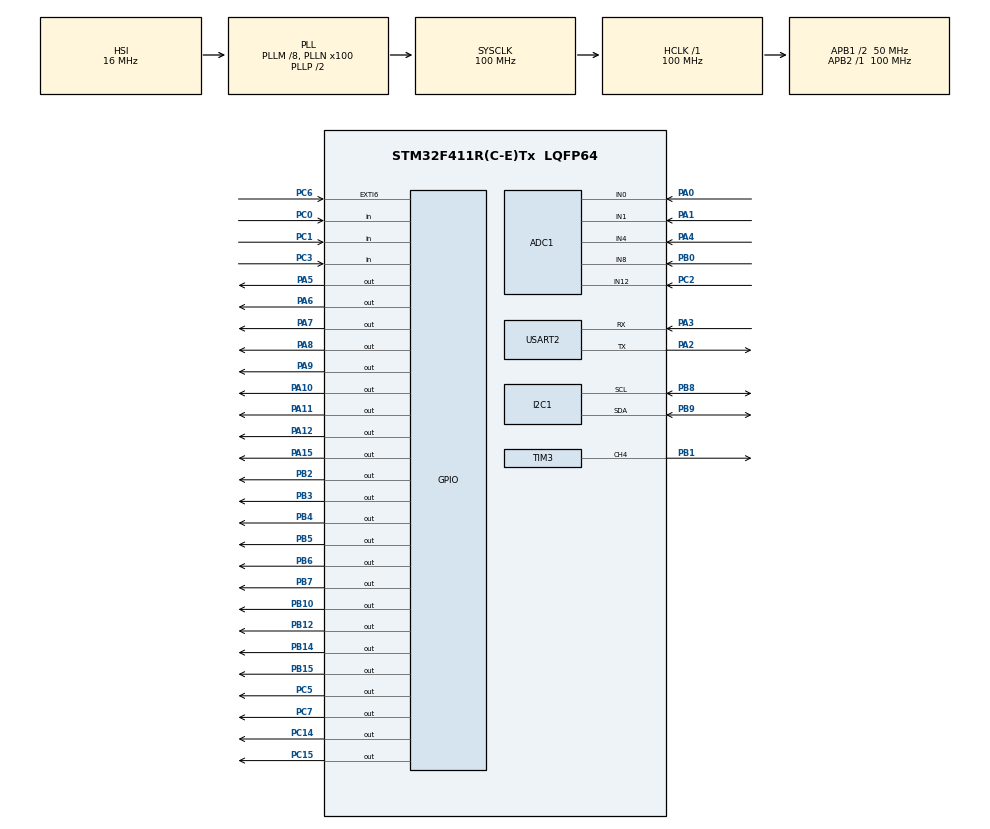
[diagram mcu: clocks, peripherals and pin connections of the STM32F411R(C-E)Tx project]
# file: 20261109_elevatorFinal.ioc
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ADC1.Channel-0\#ChannelRegularConversion=ADC_CHANNEL_1
ADC1.Channel-3\#ChannelRegularConversion=ADC_CHANNEL_4
ADC1.Channel-4\#ChannelRegularConversion=ADC_CHANNEL_8
ADC1.Channel-5\#ChannelRegularConversion=ADC_CHANNEL_12
ADC1.Channel-6\#ChannelRegularConversion=ADC_CHANNEL_0
ADC1.ContinuousConvMode=ENABLE
ADC1.DMAContinuousRequests=ENABLE
ADC1.NbrOfConversion=5
ADC1.NbrOfConversionFlag=1
ADC1.Rank-3\#ChannelRegularConversion=2
ADC1.Rank-4\#ChannelRegularConversion=3
ADC1.Rank-5\#ChannelRegularConversion=4
ADC1.Rank-6\#ChannelRegularConversion=5
ADC1.SamplingTime-0\#ChannelRegularConversion=ADC_SAMPLETIME_480CYCLES
ADC1.SamplingTime-3\#ChannelRegularConversion=ADC_SAMPLETIME_480CYCLES
ADC1.SamplingTime-4\#ChannelRegularConversion=ADC_SAMPLETIME_480CYCLES
ADC1.SamplingTime-5\#ChannelRegularConversion=ADC_SAMPLETIME_480CYCLES
ADC1.SamplingTime-6\#ChannelRegularConversion=ADC_SAMPLETIME_480CYCLES
ADC1.master=1
Dma.ADC1.0.Direction=DMA_PERIPH_TO_MEMORY
Dma.ADC1.0.FIFOMode=DMA_FIFOMODE_DISABLE
Dma.ADC1.0.Instance=DMA2_Stream0
Dma.ADC1.0.MemDataAlignment=DMA_MDATAALIGN_HALFWORD
Dma.ADC1.0.MemInc=DMA_MINC_ENABLE
Dma.ADC1.0.Mode=DMA_CIRCULAR
Dma.ADC1.0.PeriphDataAlignment=DMA_PDATAALIGN_HALFWORD
Dma.ADC1.0.PeriphInc=DMA_PINC_DISABLE
Dma.ADC1.0.Priority=DMA_PRIORITY_LOW
Dma.Request0=ADC1
Mcu.Family=STM32F4
Mcu.Name=STM32F411R(C-E)Tx
Mcu.Package=LQFP64
NVIC.DMA2_Stream0_IRQn=true\:0\:0\:false\:false\:true\:false\:true\:true
NVIC.EXTI9_5_IRQn=true\:0\:0\:false\:false\:true\:true\:true\:true
NVIC.PriorityGroup=NVIC_PRIORITYGROUP_4
NVIC.TIM2_IRQn=true\:0\:0\:false\:false\:true\:true\:true\:true
NVIC.TIM4_IRQn=true\:0\:0\:false\:false\:true\:true\:true\:true
NVIC.TIM5_IRQn=true\:0\:0\:false\:false\:true\:true\:true\:true
NVIC.USART2_IRQn=true\:0\:0\:false\:false\:true\:true\:true\:true
PA0-WKUP.Signal=ADCx_IN0
PA1.Signal=ADCx_IN1
PA10.Signal=GPIO_Output
PA11.Signal=GPIO_Output
PA12.Signal=GPIO_Output
PA15.Signal=GPIO_Output
PA2.Mode=Asynchronous
PA2.Signal=USART2_TX
PA3.Mode=Asynchronous
PA3.Signal=USART2_RX
PA4.Signal=ADCx_IN4
PA5.Signal=GPIO_Output
PA6.Signal=GPIO_Output
PA7.Signal=GPIO_Output
PA8.Signal=GPIO_Output
PA9.Signal=GPIO_Output
PB0.Signal=ADCx_IN8
PB1.Signal=S_TIM3_CH4
PB10.Signal=GPIO_Output
PB12.Signal=GPIO_Output
PB14.Signal=GPIO_Output
PB15.Signal=GPIO_Output
PB2.Signal=GPIO_Output
PB3.Signal=GPIO_Output
PB4.Signal=GPIO_Output
PB5.Signal=GPIO_Output
PB6.Signal=GPIO_Output
PB7.Signal=GPIO_Output
PB8.Mode=I2C
PB8.Signal=I2C1_SCL
PB9.Mode=I2C
PB9.Signal=I2C1_SDA
PC0.Signal=GPIO_Input
PC1.Signal=GPIO_Input
PC14-OSC32_IN.Signal=GPIO_Output
PC15-OSC32_OUT.Signal=GPIO_Output
PC2.Signal=ADCx_IN12
PC3.Signal=GPIO_Input
PC5.Signal=GPIO_Output
PC6.GPIO_ModeDefaultEXTI=GPIO_MODE_IT_RISING_FALLING
PC6.Signal=GPXTI6
PC7.Signal=GPIO_Output
PH0\ -\ OSC_IN.Mode=HSE-External-Oscillator
PH0\ -\ OSC_IN.Signal=RCC_OSC_IN
PH1\ -\ OSC_OUT.Mode=HSE-External-Oscillator
PH1\ -\ OSC_OUT.Signal=RCC_OSC_OUT
ProjectManager.HeapSize=0x200
ProjectManager.StackSize=0x400
ProjectManager.TargetToolchain=STM32CubeIDE
RCC.48MHZClocksFreq_Value=50000000
RCC.AHBFreq_Value=100000000
RCC.APB1CLKDivider=RCC_HCLK_DIV2
RCC.APB1Freq_Value=50000000
RCC.APB1TimFreq_Value=100000000
RCC.APB2Freq_Value=100000000
RCC.APB2TimFreq_Value=100000000
RCC.CortexFreq_Value=100000000
RCC.HCLKFreq_Value=100000000
RCC.HSE_VALUE=8000000
RCC.HSI_VALUE=16000000
RCC.LSE_VALUE=32768
RCC.PLLM=8
RCC.PLLN=100
RCC.SYSCLKFreq_VALUE=100000000
RCC.SYSCLKSource=RCC_SYSCLKSOURCE_PLLCLK
RCC.VCOOutputFreq_Value=200000000
SH.ADCx_IN0.0=ADC1_IN0,IN0
SH.ADCx_IN1.0=ADC1_IN1,IN1
SH.ADCx_IN12.0=ADC1_IN12,IN12
SH.ADCx_IN4.0=ADC1_IN4,IN4
SH.ADCx_IN8.0=ADC1_IN8,IN8
SH.S_TIM3_CH4.0=TIM3_CH4,PWM Generation4 CH4
TIM10.Prescaler=100-1
TIM2.Period=2000-1
TIM2.Prescaler=100-1
TIM3.Channel-PWM\ Generation4\ CH4=TIM_CHANNEL_4
TIM3.Period=65535
TIM3.Prescaler=100-1
TIM4.Period=1000-1
TIM4.Prescaler=100-1
TIM5.Period=1000-1
TIM5.Prescaler=100-1
USART2.VirtualMode=VM_ASYNC
VP_TIM10_VS_ClockSourceINT.Mode=Enable_Timer
VP_TIM2_VS_ClockSourceINT.Mode=Internal
VP_TIM3_VS_ClockSourceINT.Mode=Internal
VP_TIM4_VS_ClockSourceINT.Mode=Internal
VP_TIM5_VS_ClockSourceINT.Mode=Internal
board=custom

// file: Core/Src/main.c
/* USER CODE BEGIN Header */
/**
  ******************************************************************************
  * @file           : main.c
  * @brief          : Main program body
  ******************************************************************************
  * @attention
  *
  * Copyright (c) 2026 STMicroelectronics.
  * All rights reserved.
  *
  * This software is licensed under terms that can be found in the LICENSE file
  * in the root directory of this software component.
  * If no LICENSE file comes with this software, it is provided AS-IS.
  *
  ******************************************************************************
  */
/* USER CODE END Header */
#include "main.h"

/* USER CODE BEGIN Includes */
#include "ap/ap_main.h"
/* USER CODE END Includes */

ADC_HandleTypeDef hadc1;
DMA_HandleTypeDef hdma_adc1;

I2C_HandleTypeDef hi2c1;

TIM_HandleTypeDef htim2;
TIM_HandleTypeDef htim3;
TIM_HandleTypeDef htim4;
TIM_HandleTypeDef htim5;
TIM_HandleTypeDef htim10;

UART_HandleTypeDef huart2;

void SystemClock_Config(void);
static void MX_GPIO_Init(void);
static void MX_DMA_Init(void);
static void MX_ADC1_Init(void);
static void MX_TIM3_Init(void);
static void MX_I2C1_Init(void);
static void MX_TIM10_Init(void);
static void MX_TIM4_Init(void);
static void MX_USART2_UART_Init(void);
static void MX_TIM2_Init(void);
static void MX_TIM5_Init(void);

int main(void)
{

  /* MCU Configuration--------------------------------------------------------*/

  /* Reset of all peripherals, Initializes the Flash interface and the Systick. */
  HAL_Init();

  /* Configure the system clock */
  SystemClock_Config();

  /* Initialize all configured peripherals */
  MX_GPIO_Init();
  MX_DMA_Init();
  MX_ADC1_Init();
  MX_TIM3_Init();
  MX_I2C1_Init();
  MX_TIM10_Init();
  MX_TIM4_Init();
  MX_USART2_UART_Init();
  MX_TIM2_Init();
  MX_TIM5_Init();

  /* Infinite loop */
  /* USER CODE BEGIN WHILE */
//  ap_main();

  while (1)
  {

	  ap_main();

    /* USER CODE END WHILE */

  }
}

void SystemClock_Config(void)
{
  RCC_OscInitTypeDef RCC_OscInitStruct = {0};
  RCC_ClkInitTypeDef RCC_ClkInitStruct = {0};

  /** Configure the main internal regulator output voltage
  */
  __HAL_RCC_PWR_CLK_ENABLE();
  __HAL_PWR_VOLTAGESCALING_CONFIG(PWR_REGULATOR_VOLTAGE_SCALE1);

  /** Initializes the RCC Oscillators according to the specified parameters
  * in the RCC_OscInitTypeDef structure.
  */
  RCC_OscInitStruct.OscillatorType = RCC_OSCILLATORTYPE_HSI;
  RCC_OscInitStruct.HSIState = RCC_HSI_ON;
  RCC_OscInitStruct.HSICalibrationValue = RCC_HSICALIBRATION_DEFAULT;
  RCC_OscInitStruct.PLL.PLLState = RCC_PLL_ON;
  RCC_OscInitStruct.PLL.PLLSource = RCC_PLLSOURCE_HSI;
  RCC_OscInitStruct.PLL.PLLM = 8;
  RCC_OscInitStruct.PLL.PLLN = 100;
  RCC_OscInitStruct.PLL.PLLP = RCC_PLLP_DIV2;
  RCC_OscInitStruct.PLL.PLLQ = 4;
  if (HAL_RCC_OscConfig(&RCC_OscInitStruct) != HAL_OK)
  {
    Error_Handler();
  }

  /** Initializes the CPU, AHB and APB buses clocks
  */
  RCC_ClkInitStruct.ClockType = RCC_CLOCKTYPE_HCLK|RCC_CLOCKTYPE_SYSCLK
                              |RCC_CLOCKTYPE_PCLK1|RCC_CLOCKTYPE_PCLK2;
  RCC_ClkInitStruct.SYSCLKSource = RCC_SYSCLKSOURCE_PLLCLK;
  RCC_ClkInitStruct.AHBCLKDivider = RCC_SYSCLK_DIV1;
  RCC_ClkInitStruct.APB1CLKDivider = RCC_HCLK_DIV2;
  RCC_ClkInitStruct.APB2CLKDivider = RCC_HCLK_DIV1;

  if (HAL_RCC_ClockConfig(&RCC_ClkInitStruct, FLASH_LATENCY_3) != HAL_OK)
  {
    Error_Handler();
  }
}

static void MX_ADC1_Init(void)
{

  ADC_ChannelConfTypeDef sConfig = {0};

  /** Configure the global features of the ADC (Clock, Resolution, Data Alignment and number of conversion)
  */
  hadc1.Instance = ADC1;
  hadc1.Init.ClockPrescaler = ADC_CLOCK_SYNC_PCLK_DIV4;
  hadc1.Init.Resolution = ADC_RESOLUTION_12B;
  hadc1.Init.ScanConvMode = ENABLE;
  hadc1.Init.ContinuousConvMode = ENABLE;
  hadc1.Init.DiscontinuousConvMode = DISABLE;
  hadc1.Init.ExternalTrigConvEdge = ADC_EXTERNALTRIGCONVEDGE_NONE;
  hadc1.Init.ExternalTrigConv = ADC_SOFTWARE_START;
  hadc1.Init.DataAlign = ADC_DATAALIGN_RIGHT;
  hadc1.Init.NbrOfConversion = 5;
  hadc1.Init.DMAContinuousRequests = ENABLE;
  hadc1.Init.EOCSelection = ADC_EOC_SINGLE_CONV;
  if (HAL_ADC_Init(&hadc1) != HAL_OK)
  {
    Error_Handler();
  }

  /** Configure for the selected ADC regular channel its corresponding rank in the sequencer and its sample time.
  */
  sConfig.Channel = ADC_CHANNEL_1;
  sConfig.Rank = 1;
  sConfig.SamplingTime = ADC_SAMPLETIME_480CYCLES;
  if (HAL_ADC_ConfigChannel(&hadc1, &sConfig) != HAL_OK)
  {
    Error_Handler();
  }

  /** Configure for the selected ADC regular channel its corresponding rank in the sequencer and its sample time.
  */
  sConfig.Channel = ADC_CHANNEL_4;
  sConfig.Rank = 2;
  if (HAL_ADC_ConfigChannel(&hadc1, &sConfig) != HAL_OK)
  {
    Error_Handler();
  }

  /** Configure for the selected ADC regular channel its corresponding rank in the sequencer and its sample time.
  */
  sConfig.Channel = ADC_CHANNEL_8;
  sConfig.Rank = 3;
  if (HAL_ADC_ConfigChannel(&hadc1, &sConfig) != HAL_OK)
  {
    Error_Handler();
  }

  /** Configure for the selected ADC regular channel its corresponding rank in the sequencer and its sample time.
  */
  sConfig.Channel = ADC_CHANNEL_12;
  sConfig.Rank = 4;
  if (HAL_ADC_ConfigChannel(&hadc1, &sConfig) != HAL_OK)
  {
    Error_Handler();
  }

  /** Configure for the selected ADC regular channel its corresponding rank in the sequencer and its sample time.
  */
  sConfig.Channel = ADC_CHANNEL_0;
  sConfig.Rank = 5;
  if (HAL_ADC_ConfigChannel(&hadc1, &sConfig) != HAL_OK)
  {
    Error_Handler();
  }

}

static void MX_I2C1_Init(void)
{

  hi2c1.Instance = I2C1;
  hi2c1.Init.ClockSpeed = 100000;
  hi2c1.Init.DutyCycle = I2C_DUTYCYCLE_2;
  hi2c1.Init.OwnAddress1 = 0;
  hi2c1.Init.AddressingMode = I2C_ADDRESSINGMODE_7BIT;
  hi2c1.Init.DualAddressMode = I2C_DUALADDRESS_DISABLE;
  hi2c1.Init.OwnAddress2 = 0;
  hi2c1.Init.GeneralCallMode = I2C_GENERALCALL_DISABLE;
  hi2c1.Init.NoStretchMode = I2C_NOSTRETCH_DISABLE;
  if (HAL_I2C_Init(&hi2c1) != HAL_OK)
  {
    Error_Handler();
  }

}

static void MX_TIM2_Init(void)
{

  TIM_ClockConfigTypeDef sClockSourceConfig = {0};
  TIM_MasterConfigTypeDef sMasterConfig = {0};

  htim2.Instance = TIM2;
  htim2.Init.Prescaler = 100-1;
  htim2.Init.CounterMode = TIM_COUNTERMODE_UP;
  htim2.Init.Period = 2000-1;
  htim2.Init.ClockDivision = TIM_CLOCKDIVISION_DIV1;
  htim2.Init.AutoReloadPreload = TIM_AUTORELOAD_PRELOAD_DISABLE;
  if (HAL_TIM_Base_Init(&htim2) != HAL_OK)
  {
    Error_Handler();
  }
  sClockSourceConfig.ClockSource = TIM_CLOCKSOURCE_INTERNAL;
  if (HAL_TIM_ConfigClockSource(&htim2, &sClockSourceConfig) != HAL_OK)
  {
    Error_Handler();
  }
  sMasterConfig.MasterOutputTrigger = TIM_TRGO_RESET;
  sMasterConfig.MasterSlaveMode = TIM_MASTERSLAVEMODE_DISABLE;
  if (HAL_TIMEx_MasterConfigSynchronization(&htim2, &sMasterConfig) != HAL_OK)
  {
    Error_Handler();
  }

}

static void MX_TIM3_Init(void)
{

  TIM_ClockConfigTypeDef sClockSourceConfig = {0};
  TIM_MasterConfigTypeDef sMasterConfig = {0};
  TIM_OC_InitTypeDef sConfigOC = {0};

  htim3.Instance = TIM3;
  htim3.Init.Prescaler = 100-1;
  htim3.Init.CounterMode = TIM_COUNTERMODE_UP;
  htim3.Init.Period = 65535;
  htim3.Init.ClockDivision = TIM_CLOCKDIVISION_DIV1;
  htim3.Init.AutoReloadPreload = TIM_AUTORELOAD_PRELOAD_DISABLE;
  if (HAL_TIM_Base_Init(&htim3) != HAL_OK)
  {
    Error_Handler();
  }
  sClockSourceConfig.ClockSource = TIM_CLOCKSOURCE_INTERNAL;
  if (HAL_TIM_ConfigClockSource(&htim3, &sClockSourceConfig) != HAL_OK)
  {
    Error_Handler();
  }
  if (HAL_TIM_PWM_Init(&htim3) != HAL_OK)
  {
    Error_Handler();
  }
  sMasterConfig.MasterOutputTrigger = TIM_TRGO_RESET;
  sMasterConfig.MasterSlaveMode = TIM_MASTERSLAVEMODE_DISABLE;
  if (HAL_TIMEx_MasterConfigSynchronization(&htim3, &sMasterConfig) != HAL_OK)
  {
    Error_Handler();
  }
  sConfigOC.OCMode = TIM_OCMODE_PWM1;
  sConfigOC.Pulse = 0;
  sConfigOC.OCPolarity = TIM_OCPOLARITY_HIGH;
  sConfigOC.OCFastMode = TIM_OCFAST_DISABLE;
  if (HAL_TIM_PWM_ConfigChannel(&htim3, &sConfigOC, TIM_CHANNEL_4) != HAL_OK)
  {
    Error_Handler();
  }
  HAL_TIM_MspPostInit(&htim3);

}

static void MX_TIM4_Init(void)
{

  TIM_ClockConfigTypeDef sClockSourceConfig = {0};
  TIM_MasterConfigTypeDef sMasterConfig = {0};

  htim4.Instance = TIM4;
  htim4.Init.Prescaler = 100-1;
  htim4.Init.CounterMode = TIM_COUNTERMODE_UP;
  htim4.Init.Period = 1000-1;
  htim4.Init.ClockDivision = TIM_CLOCKDIVISION_DIV1;
  htim4.Init.AutoReloadPreload = TIM_AUTORELOAD_PRELOAD_DISABLE;
  if (HAL_TIM_Base_Init(&htim4) != HAL_OK)
  {
    Error_Handler();
  }
  sClockSourceConfig.ClockSource = TIM_CLOCKSOURCE_INTERNAL;
  if (HAL_TIM_ConfigClockSource(&htim4, &sClockSourceConfig) != HAL_OK)
  {
    Error_Handler();
  }
  sMasterConfig.MasterOutputTrigger = TIM_TRGO_RESET;
  sMasterConfig.MasterSlaveMode = TIM_MASTERSLAVEMODE_DISABLE;
  if (HAL_TIMEx_MasterConfigSynchronization(&htim4, &sMasterConfig) != HAL_OK)
  {
    Error_Handler();
  }

}

static void MX_TIM5_Init(void)
{

  TIM_ClockConfigTypeDef sClockSourceConfig = {0};
  TIM_MasterConfigTypeDef sMasterConfig = {0};

  htim5.Instance = TIM5;
  htim5.Init.Prescaler = 100-1;
  htim5.Init.CounterMode = TIM_COUNTERMODE_UP;
  htim5.Init.Period = 1000-1;
  htim5.Init.ClockDivision = TIM_CLOCKDIVISION_DIV1;
  htim5.Init.AutoReloadPreload = TIM_AUTORELOAD_PRELOAD_DISABLE;
  if (HAL_TIM_Base_Init(&htim5) != HAL_OK)
  {
    Error_Handler();
  }
  sClockSourceConfig.ClockSource = TIM_CLOCKSOURCE_INTERNAL;
  if (HAL_TIM_ConfigClockSource(&htim5, &sClockSourceConfig) != HAL_OK)
  {
    Error_Handler();
  }
  sMasterConfig.MasterOutputTrigger = TIM_TRGO_RESET;
  sMasterConfig.MasterSlaveMode = TIM_MASTERSLAVEMODE_DISABLE;
  if (HAL_TIMEx_MasterConfigSynchronization(&htim5, &sMasterConfig) != HAL_OK)
  {
    Error_Handler();
  }

}

static void MX_TIM10_Init(void)
{

  htim10.Instance = TIM10;
  htim10.Init.Prescaler = 100-1;
  htim10.Init.CounterMode = TIM_COUNTERMODE_UP;
  htim10.Init.Period = 65535;
  htim10.Init.ClockDivision = TIM_CLOCKDIVISION_DIV1;
  htim10.Init.AutoReloadPreload = TIM_AUTORELOAD_PRELOAD_DISABLE;
  if (HAL_TIM_Base_Init(&htim10) != HAL_OK)
  {
    Error_Handler();
  }

}

static void MX_USART2_UART_Init(void)
{

  huart2.Instance = USART2;
  huart2.Init.BaudRate = 115200;
  huart2.Init.WordLength = UART_WORDLENGTH_8B;
  huart2.Init.StopBits = UART_STOPBITS_1;
  huart2.Init.Parity = UART_PARITY_NONE;
  huart2.Init.Mode = UART_MODE_TX_RX;
  huart2.Init.HwFlowCtl = UART_HWCONTROL_NONE;
  huart2.Init.OverSampling = UART_OVERSAMPLING_16;
  if (HAL_UART_Init(&huart2) != HAL_OK)
  {
    Error_Handler();
  }

}

static void MX_DMA_Init(void)
{

  /* DMA controller clock enable */
  __HAL_RCC_DMA2_CLK_ENABLE();

  /* DMA interrupt init */
  /* DMA2_Stream0_IRQn interrupt configuration */
  HAL_NVIC_SetPriority(DMA2_Stream0_IRQn, 0, 0);
  HAL_NVIC_EnableIRQ(DMA2_Stream0_IRQn);

}

static void MX_GPIO_Init(void)
{
  GPIO_InitTypeDef GPIO_InitStruct = {0};

  /* GPIO Ports Clock Enable */
  __HAL_RCC_GPIOC_CLK_ENABLE();
  __HAL_RCC_GPIOH_CLK_ENABLE();
  __HAL_RCC_GPIOA_CLK_ENABLE();
  __HAL_RCC_GPIOB_CLK_ENABLE();

  /*Configure GPIO pin Output Level */
  HAL_GPIO_WritePin(GPIOC, GPIO_PIN_14|GPIO_PIN_15|GPIO_PIN_5|GPIO_PIN_7, GPIO_PIN_RESET);

  /*Configure GPIO pin Output Level */
  HAL_GPIO_WritePin(GPIOA, GPIO_PIN_5|GPIO_PIN_6|GPIO_PIN_7|GPIO_PIN_8
                          |GPIO_PIN_9|GPIO_PIN_10|GPIO_PIN_11|GPIO_PIN_12
                          |GPIO_PIN_15, GPIO_PIN_RESET);

  /*Configure GPIO pin Output Level */
  HAL_GPIO_WritePin(GPIOB, GPIO_PIN_2|GPIO_PIN_10|GPIO_PIN_12|GPIO_PIN_14
                          |GPIO_PIN_15|GPIO_PIN_3|GPIO_PIN_4|GPIO_PIN_5
                          |GPIO_PIN_6|GPIO_PIN_7, GPIO_PIN_RESET);

  /*Configure GPIO pins : PC14 PC15 PC5 PC7 */
  GPIO_InitStruct.Pin = GPIO_PIN_14|GPIO_PIN_15|GPIO_PIN_5|GPIO_PIN_7;
  GPIO_InitStruct.Mode = GPIO_MODE_OUTPUT_PP;
  GPIO_InitStruct.Pull = GPIO_NOPULL;
  GPIO_InitStruct.Speed = GPIO_SPEED_FREQ_LOW;
  HAL_GPIO_Init(GPIOC, &GPIO_InitStruct);

  /*Configure GPIO pins : PC0 PC1 PC3 */
  GPIO_InitStruct.Pin = GPIO_PIN_0|GPIO_PIN_1|GPIO_PIN_3;
  GPIO_InitStruct.Mode = GPIO_MODE_INPUT;
  GPIO_InitStruct.Pull = GPIO_NOPULL;
  HAL_GPIO_Init(GPIOC, &GPIO_InitStruct);

  /*Configure GPIO pins : PA5 PA6 PA7 PA8
                           PA9 PA10 PA11 PA12
                           PA15 */
  GPIO_InitStruct.Pin = GPIO_PIN_5|GPIO_PIN_6|GPIO_PIN_7|GPIO_PIN_8
                          |GPIO_PIN_9|GPIO_PIN_10|GPIO_PIN_11|GPIO_PIN_12
                          |GPIO_PIN_15;
  GPIO_InitStruct.Mode = GPIO_MODE_OUTPUT_PP;
  GPIO_InitStruct.Pull = GPIO_NOPULL;
  GPIO_InitStruct.Speed = GPIO_SPEED_FREQ_LOW;
  HAL_GPIO_Init(GPIOA, &GPIO_InitStruct);

  /*Configure GPIO pins : PB2 PB10 PB12 PB14
                           PB15 PB3 PB4 PB5
                           PB6 PB7 */
  GPIO_InitStruct.Pin = GPIO_PIN_2|GPIO_PIN_10|GPIO_PIN_12|GPIO_PIN_14
                          |GPIO_PIN_15|GPIO_PIN_3|GPIO_PIN_4|GPIO_PIN_5
                          |GPIO_PIN_6|GPIO_PIN_7;
  GPIO_InitStruct.Mode = GPIO_MODE_OUTPUT_PP;
  GPIO_InitStruct.Pull = GPIO_NOPULL;
  GPIO_InitStruct.Speed = GPIO_SPEED_FREQ_LOW;
  HAL_GPIO_Init(GPIOB, &GPIO_InitStruct);

  /*Configure GPIO pin : PC6 */
  GPIO_InitStruct.Pin = GPIO_PIN_6;
  GPIO_InitStruct.Mode = GPIO_MODE_IT_RISING_FALLING;
  GPIO_InitStruct.Pull = GPIO_NOPULL;
  HAL_GPIO_Init(GPIOC, &GPIO_InitStruct);

  /* EXTI interrupt init*/
  HAL_NVIC_SetPriority(EXTI9_5_IRQn, 0, 0);
  HAL_NVIC_EnableIRQ(EXTI9_5_IRQn);

}

void Error_Handler(void)
{
  __disable_irq();
  while (1)
  {
  }
}
